# STM32F7x7 register map
File version: 1.6
CPU: CM7 r0p0, little endian, no MPU, no FPU, 3 interrupt priority bits
Registers are 32-bit, read-write, reset 0x0 unless marked. A register's access mark holds for its fields unless they carry their own. Offsets are from the block's base; [hi:lo] are bit positions.

## SPI1 — Serial peripheral interface
Base 0x40013000
Same registers: SPI2 0x40003800, SPI3 0x40003C00, SPI4 0x40013400, SPI5 0x40015000, SPI6 0x40015400
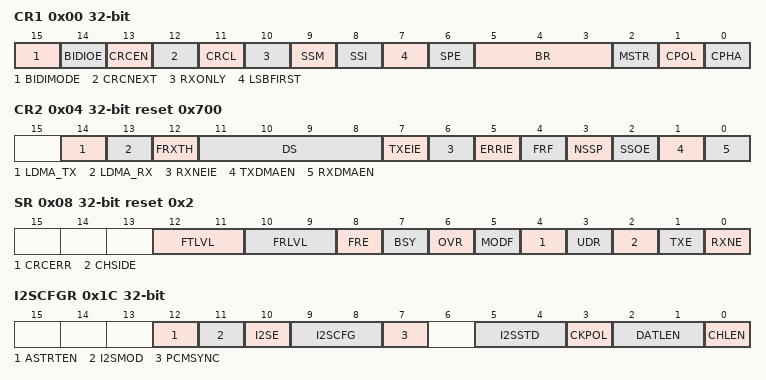
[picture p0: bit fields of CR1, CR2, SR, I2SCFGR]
0x00 CR1 — control register 1
  [15] BIDIMODE — Bidirectional data mode enable
  [14] BIDIOE — Output enable in bidirectional mode
  [13] CRCEN — Hardware CRC calculation enable
  [12] CRCNEXT — CRC transfer next
  [11] CRCL — CRC length
  [10] RXONLY — Receive only
  [9] SSM — Software slave management
  [8] SSI — Internal slave select
  [7] LSBFIRST — Frame format
  [6] SPE — SPI enable
  [5:3] BR — Baud rate control
  [2] MSTR — Master selection
  [1] CPOL — Clock polarity
  [0] CPHA — Clock phase
0x04 CR2 reset 0x700 — control register 2
  [14] LDMA_TX — Last DMA transfer for transmission
  [13] LDMA_RX — Last DMA transfer for reception
  [12] FRXTH — FIFO reception threshold
  [11:8] DS — Data size
  [7] TXEIE — Tx buffer empty interrupt enable
  [6] RXNEIE — RX buffer not empty interrupt enable
  [5] ERRIE — Error interrupt enable
  [4] FRF — Frame format
  [3] NSSP — NSS pulse management
  [2] SSOE — SS output enable
  [1] TXDMAEN — Tx buffer DMA enable
  [0] RXDMAEN — Rx buffer DMA enable
0x08 SR access per field reset 0x2 — status register
  [12:11] FTLVL ro — FIFO Transmission Level
  [10:9] FRLVL ro — FIFO reception level
  [8] FRE ro — Frame format error
  [7] BSY ro — Busy flag
  [6] OVR ro — Overrun flag
  [5] MODF ro — Mode fault
  [4] CRCERR rw — CRC error flag
  [3] UDR ro — Underrun flag
  [2] CHSIDE ro — Channel side
  [1] TXE ro — Transmit buffer empty
  [0] RXNE ro — Receive buffer not empty
0x0C DR — data register
  [15:0] DR — Data register
0x10 CRCPR reset 0x7 — CRC polynomial register
  [15:0] CRCPOLY
0x14 RXCRCR ro — RX CRC register
  [15:0] RxCRC
0x18 TXCRCR ro — TX CRC register
  [15:0] TxCRC
0x1C I2SCFGR — I2S configuration register
  [12] ASTRTEN — Asynchronous start enable
  [11] I2SMOD — I2S mode selection
  [10] I2SE — I2S Enable
  [9:8] I2SCFG — I2S configuration mode
  [7] PCMSYNC — PCM frame synchronization
  [5:4] I2SSTD — I2S standard selection
  [3] CKPOL — Steady state clock polarity
  [2:1] DATLEN — Data length to be transferred
  [0] CHLEN — Channel length (number of bits per audio channel)
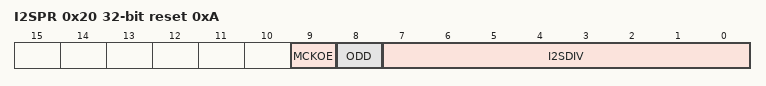
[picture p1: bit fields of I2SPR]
0x20 I2SPR reset 0xA — I2S prescaler register
  [9] MCKOE — Master clock output enable
  [8] ODD — Odd factor for the prescaler
  [7:0] I2SDIV — I2S Linear prescaler

## C_ADC — Common ADC registers
Base 0x40012300
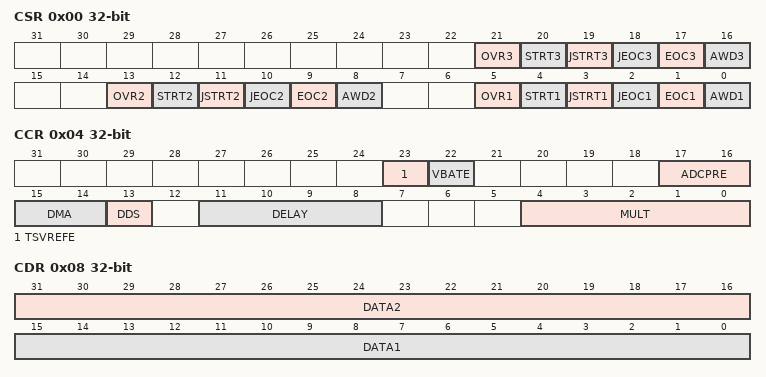
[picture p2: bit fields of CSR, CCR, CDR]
0x00 CSR ro — ADC Common status register
  [21] OVR3 — Overrun flag of ADC3
  [20] STRT3 — Regular channel Start flag of ADC 3
  [19] JSTRT3 — Injected channel Start flag of ADC 3
  [18] JEOC3 — Injected channel end of conversion of ADC 3
  [17] EOC3 — End of conversion of ADC 3
  [16] AWD3 — Analog watchdog flag of ADC 3
  [13] OVR2 — Overrun flag of ADC 2
  [12] STRT2 — Regular channel Start flag of ADC 2
  [11] JSTRT2 — Injected channel Start flag of ADC 2
  [10] JEOC2 — Injected channel end of conversion of ADC 2
  [9] EOC2 — End of conversion of ADC 2
  [8] AWD2 — Analog watchdog flag of ADC 2
  [5] OVR1 — Overrun flag of ADC 1
  [4] STRT1 — Regular channel Start flag of ADC 1
  [3] JSTRT1 — Injected channel Start flag of ADC 1
  [2] JEOC1 — Injected channel end of conversion of ADC 1
  [1] EOC1 — End of conversion of ADC 1
  [0] AWD1 — Analog watchdog flag of ADC 1
0x04 CCR — ADC common control register
  [23] TSVREFE — Temperature sensor and VREFINT enable
  [22] VBATE — VBAT enable
  [17:16] ADCPRE — ADC prescaler
  [15:14] DMA — Direct memory access mode for multi ADC mode
  [13] DDS — DMA disable selection for multi-ADC mode
  [11:8] DELAY — Delay between 2 sampling phases
  [4:0] MULT — Multi ADC mode selection
0x08 CDR ro — ADC common regular data register for dual and triple modes
  [31:16] DATA2 — 2nd data item of a pair of regular conversions
  [15:0] DATA1 — 1st data item of a pair of regular conversions
